# N572F072_v3 register map
File version: 1.0
Registers are 32-bit, read-write, reset 0x0 unless marked. A register's access mark holds for its fields unless they carry their own. Offsets are from the block's base; [hi:lo] are bit positions; 'fields as' and 'values as' point back to an identical list.

## CLK — CLK Register Map
Base 0x50000200
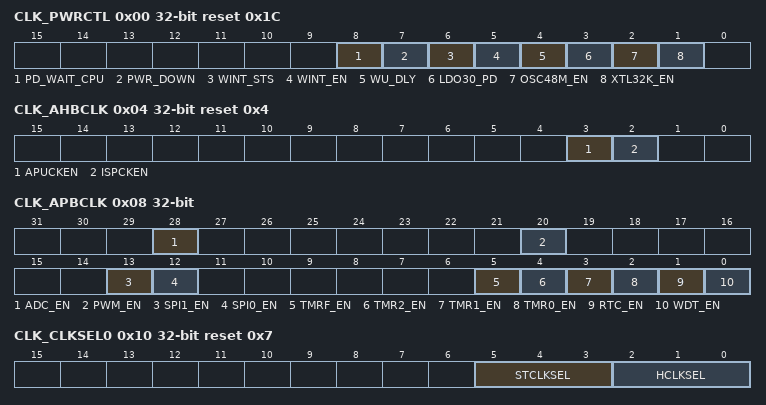
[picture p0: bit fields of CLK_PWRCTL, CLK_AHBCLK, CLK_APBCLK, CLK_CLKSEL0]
0x00 CLK_PWRCTL reset 0x1C — System Power Control Register
  [8] PD_WAIT_CPU — This Bit Controls The Power Down Entry Condition. Please refer to PWR_DOWN bit for the usage of PD_WAIT_CPU bit. The following is a brief description of PD_WAIT_CPU bit.
    0=Chip is at normal mode. Note that PWR_DOWN cannot be set to 1 when PD_WAIT_CPU value remains at 0, otherwise the chip may not wake up normally; 1=Chip waits to enter power-down mode
  [7] PWR_DOWN — System Power Down Active Or Enable Bit
    0=Chip operates at normal mode; 1=Chip is standing by power-down entry condition
  [6] WINT_STS — Chip Power Down Wake Up Status Flag. Set by "power down wake up", it indicates that resume from power down mode. The flag is set if the GPIO, WDT or RTC wakeup. Note: Write 1 to clear the bit.
  [5] WINT_EN — Enable Interrupt When Wake Up From Power Down Mode
    0=Disable,; 1=Enable. The interrupt will occur when MCU wakes up from power down mode
  [4] WU_DLY — Enable The Wake Up Delay Counter. When the chip wakes up from idle mode, the clock control will delay some clock cycles to wait the internal 48MHz oscillator clock stable.
    0=Disable the clock cycles delay; 1=Enable the clock cycles delay, the delay is 512 clock cycles
  [3] LDO30_PD — Driving Out 3.0V (Through LDO30E Pad) LDO Control. After reset, this bit is "1".
    0=3.0V LDO (LDO30) is enabled; 1=3.0V LDO (LDO30) is disabled
  [2] OSC48M_EN — Internal 48MHz RC Oscillator Control. After reset, this bit is "1".
    0=48MHz oscillation is disabled; 1=48MHz oscillation is enabled
  [1] XTL32K_EN — External 32.768KHz Crystal Control. After reset, this bit is "0".
    0=32.768KHz Crystal is disabled; 1=32.768KHz Crystal is enabled
0x04 CLK_AHBCLK reset 0x4 — AHB Device Clock Enable Control Register
  [3] APUCKEN — APU Clock Enable Control
    0=To disable the APU engine clock; 1=To enable the APU engine clock
  [2] ISPCKEN — Flash ISP Engine Clock Enable Control
    0=To disable the Flash ISP engine clock; 1=To enable the Flash ISP engine clock
0x08 CLK_APBCLK — APB Device Clock Enable Control Register
  [all] fields
    0=Disable; 1=Enable
  [28] ADC_EN — Audio Analog-Digital-Converter (ADC) Clock Enable Control
  [20] PWM_EN — PWM Block Clock Enable Control
  [13] SPI1_EN — SPI1 Clock Enable Control
  [12] SPI0_EN — SPI0 Clock Enable Control
  [5] TMRF_EN — TimerF Clock Enable Control
  [4] TMR2_EN — Timer2 Clock Enable Control
  [3] TMR1_EN — Timer1 Clock Enable Control
  [2] TMR0_EN — Timer0 Clock Enable Control
  [1] RTC_EN — Real-Time-Clock APB Interface Clock Control. This bit is used to control the RTC APB clock only. The RTC engine clock source is from the 32.768KHz crystal.
  [0] WDT_EN — Watchdog Clock Enable Control. This bit is the protected bit. To program this bit needs an open lock sequence, write "59h", "16h", "88h" to register SYS_REGLCTL to un-lock this bit. Refer to the register SYS_REGLCTL at address SYS_BA+0x100. The default bit value is set according to the Flash Controller User Configuration Register CONFIG[31].
0x10 CLK_CLKSEL0 reset 0x7 — Clock Source Select Control Register 0
  [5:3] STCLKSEL — MCU Cortex_M0 SysTick Clock Source Select
    0=Clock source from HCLK/2; 1=Clock source from XTL_32K. Clock source from RC_48M/8
  [2:0] HCLKSEL — HCLK Clock Source Select . Note: 1. When power on, 48MHz RC is selected as HCLK clock source. 2. Before clock switch, the related clock sources (pre-select and new-select) must be turned on.
    0=Clock source from XTL_32K; 2=Clock source from PLL1_FOUT; 4=Clock source from PLL2_FOUT; 7=Clock source from RC_48M
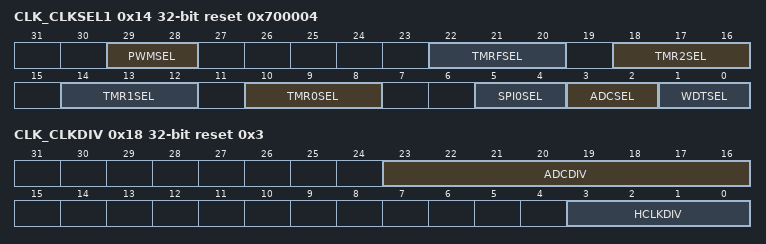
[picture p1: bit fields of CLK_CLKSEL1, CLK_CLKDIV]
0x14 CLK_CLKSEL1 reset 0x700004 — Clock Source Select Control Register 1
  [29:28] PWMSEL — PWM Timer Clock Source Select
    0=Clock source from HCLK; 1=Clock source from XTL_32K; 2=Equivalent with "00"; 3=Clock source from RC_48M
  [22:20] TMRFSEL — TimerF Clock Source Select
    0=Clock source from external XTL_32K/32,; 1=Clock source from external XTL_32K/(4x32),; 6=Clock source from RC_48M/65536,; 7=Clock source from RC_48M/(4x65536),
  [18:16] TMR2SEL — Timer2 Clock Source Select
    0=Clock source from HCLK; 1=Clock source from XTL_32K. Clock source from RC_48M; 2=Equivalent with "000"; 3=Clock source from external trigger
  [14:12] TMR1SEL — Timer1 Clock Source Select
    values as TMR2SEL
  [10:8] TMR0SEL — Timer0 Clock Source Select
    values as TMR2SEL
  [5:4] SPI0SEL — SPI0 Clock Source Select
    0=Clock source from HCLK; 1=Clock source from PLL2_FOUT. Clock source from RC_48M
  [3:2] ADCSEL — ADC Clock Source Select
    0=Clock source from PLL2_FOUT,; 1=Clock source from HCLK,. Clock source from RC_48M
  [1:0] WDTSEL — Watchdog Timer Clock Source Selection (Write Protect). These bits are protected bits. To program these bits needs an open lock sequence, write "59h", "16h", "88h" to SYS_REGLCTL to un-lock these bits. Refer to the register SYS_REGLCTL at address SYS_BA+0x100..
    0=Clock source from HCLK/2048,; 1=Clock source from XTL_32K,; 2=Clock source from PLL1_FOUT,; 3=Clock source from RC_48M/2
0x18 CLK_CLKDIV reset 0x3 — Clock Divider Number Register
  [23:16] ADCDIV — ADC Clock Divide Number From ADC Clock Source
  [3:0] HCLKDIV — HCLK Clock Divide Number From HCLK Clock Source
0x20 CLK_PLLCON reset 0x3 — PLL Control Register
